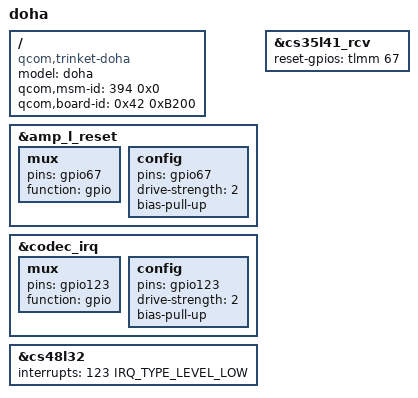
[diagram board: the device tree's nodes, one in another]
/* Copyright (c) 2018, The Linux Foundation. All rights reserved.
 *
 * This program is free software; you can redistribute it and/or modify
 * it under the terms of the GNU General Public License version 2 and
 * only version 2 as published by the Free Software Foundation.
 *
 * This program is distributed in the hope that it will be useful,
 * but WITHOUT ANY WARRANTY; without even the implied warranty of
 * MERCHANTABILITY or FITNESS FOR A PARTICULAR PURPOSE.  See the
 * GNU General Public License for more details.
 */

/dts-v1/;
/plugin/;

#include <dt-bindings/clock/qcom,gcc-trinket.h>
#include "trinket-doha-common-overlay.dtsi"

/ {
	model = "doha";
	compatible = "qcom,trinket-doha", "qcom,trinket-moto", "qcom,trinket";
	qcom,msm-id = <394 0x0>;
	qcom,board-id = <0x42 0xB200>;
};

&amp_l_reset {
	mux {
		pins = "gpio67";
		function = "gpio";
	};
	config {
		pins = "gpio67";
		drive-strength = <2>; /* 2 MA */
		bias-pull-up;
	};
};

&codec_irq {
	mux {
		pins = "gpio123";
		function = "gpio";
	};
	config {
		pins = "gpio123";
		drive-strength = <2>; /* 2 MA */
		bias-pull-up;
	};
};

/* cant use the low level trigger on the old hardware as it cause the power issue */
&cs48l32 {
	interrupts = <123 IRQ_TYPE_LEVEL_LOW>;
};

&cs35l41_rcv {
	reset-gpios = <&tlmm 67 0>;
};
